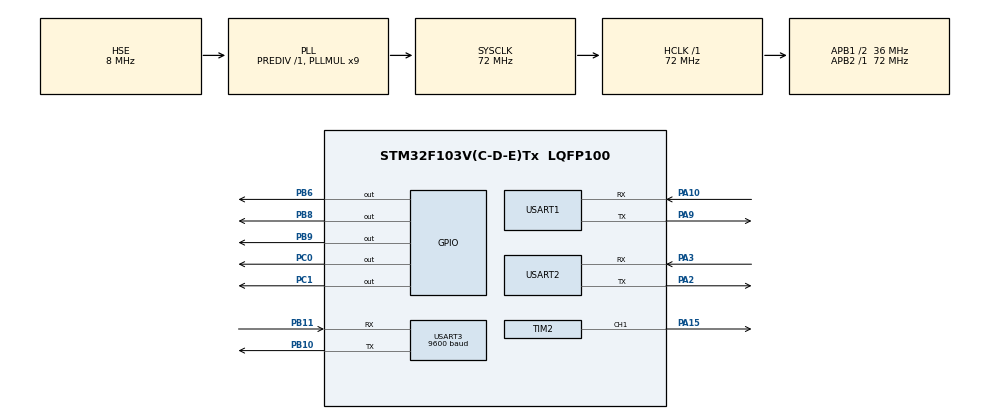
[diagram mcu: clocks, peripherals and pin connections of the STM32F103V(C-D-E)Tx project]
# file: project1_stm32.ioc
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IWDG.Prescaler=IWDG_PRESCALER_64
Mcu.Family=STM32F1
Mcu.Name=STM32F103V(C-D-E)Tx
Mcu.Package=LQFP100
NVIC.PriorityGroup=NVIC_PRIORITYGROUP_4
NVIC.TIM7_IRQn=true\:15\:0\:false\:false\:true\:false\:true\:true
NVIC.TimeBase=TIM7_IRQn
NVIC.TimeBaseIP=TIM7
NVIC.USART2_IRQn=true\:7\:0\:true\:false\:true\:true\:true\:true
NVIC.USART3_IRQn=true\:6\:0\:true\:false\:true\:true\:true\:true
OSC_IN.Mode=HSE-External-Oscillator
OSC_IN.Signal=RCC_OSC_IN
OSC_OUT.Mode=HSE-External-Oscillator
OSC_OUT.Signal=RCC_OSC_OUT
PA10.Mode=Asynchronous
PA10.Signal=USART1_RX
PA13.Mode=Serial_Wire
PA13.Signal=SYS_JTMS-SWDIO
PA14.Mode=Serial_Wire
PA14.Signal=SYS_JTCK-SWCLK
PA15.Signal=S_TIM2_CH1_ETR
PA2.Mode=Asynchronous
PA2.Signal=USART2_TX
PA3.Mode=Asynchronous
PA3.Signal=USART2_RX
PA9.Mode=Asynchronous
PA9.Signal=USART1_TX
PB10.Mode=Asynchronous
PB10.Signal=USART3_TX
PB11.Mode=Asynchronous
PB11.Signal=USART3_RX
PB6.GPIO_ModeDefaultOutputPP=GPIO_MODE_OUTPUT_OD
PB6.GPIO_PuPd=GPIO_PULLUP
PB6.GPIO_Speed=GPIO_SPEED_FREQ_HIGH
PB6.PinState=GPIO_PIN_SET
PB6.Signal=GPIO_Output
PB8.GPIO_ModeDefaultOutputPP=GPIO_MODE_OUTPUT_OD
PB8.GPIO_PuPd=GPIO_PULLUP
PB8.GPIO_Speed=GPIO_SPEED_FREQ_HIGH
PB8.PinState=GPIO_PIN_SET
PB8.Signal=GPIO_Output
PB9.GPIO_ModeDefaultOutputPP=GPIO_MODE_OUTPUT_OD
PB9.GPIO_PuPd=GPIO_PULLUP
PB9.GPIO_Speed=GPIO_SPEED_FREQ_HIGH
PB9.PinState=GPIO_PIN_SET
PB9.Signal=GPIO_Output
PC0.Signal=GPIO_Output
PC1.GPIO_ModeDefaultOutputPP=GPIO_MODE_OUTPUT_OD
PC1.GPIO_PuPd=GPIO_PULLUP
PC1.GPIO_Speed=GPIO_SPEED_FREQ_HIGH
PC1.PinState=GPIO_PIN_SET
PC1.Signal=GPIO_Output
PC14-OSC32_IN.Mode=LSE-External-Oscillator
PC14-OSC32_IN.Signal=RCC_OSC32_IN
PC15-OSC32_OUT.Mode=LSE-External-Oscillator
PC15-OSC32_OUT.Signal=RCC_OSC32_OUT
ProjectManager.HeapSize=0x200
ProjectManager.StackSize=0x400
ProjectManager.TargetToolchain=CMake
RCC.AHBFreq_Value=72000000
RCC.APB1CLKDivider=RCC_HCLK_DIV2
RCC.APB1Freq_Value=36000000
RCC.APB1TimFreq_Value=72000000
RCC.APB2Freq_Value=72000000
RCC.APB2TimFreq_Value=72000000
RCC.HCLKFreq_Value=72000000
RCC.PLLMUL=RCC_PLL_MUL9
RCC.PLLSourceVirtual=RCC_PLLSOURCE_HSE
RCC.SYSCLKFreq_VALUE=72000000
RCC.SYSCLKSource=RCC_SYSCLKSOURCE_PLLCLK
RCC.USBFreq_Value=72000000
SH.S_TIM2_CH1_ETR.0=TIM2_CH1,PWM Generation1 CH1
TIM2.AutoReloadPreload=TIM_AUTORELOAD_PRELOAD_ENABLE
TIM2.Channel-PWM\ Generation1\ CH1=TIM_CHANNEL_1
TIM2.Period=19999
TIM2.Prescaler=71
TIM6.AutoReloadPreload=TIM_AUTORELOAD_PRELOAD_ENABLE
TIM6.Prescaler=71
USART1.VirtualMode=VM_ASYNC
USART2.VirtualMode=VM_ASYNC
USART3.BaudRate=9600
USART3.VirtualMode=VM_ASYNC
VP_IWDG_VS_IWDG.Mode=IWDG_Activate
VP_SYS_VS_tim7.Mode=TIM7
VP_TIM2_VS_ClockSourceINT.Mode=Internal
VP_TIM6_VS_ClockSourceINT.Mode=Enable_Timer
board=custom

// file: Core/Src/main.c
/* USER CODE BEGIN Header */
/**
  ******************************************************************************
  * @file           : main.c
  * @brief          : Main program body
  ******************************************************************************
  * @attention
  *
  * Copyright (c) 2026 STMicroelectronics.
  * All rights reserved.
  *
  * This software is licensed under terms that can be found in the LICENSE file
  * in the root directory of this software component.
  * If no LICENSE file comes with this software, it is provided AS-IS.
  *
  ******************************************************************************
  */
/* USER CODE END Header */
#include "main.h"
#include "iwdg.h"
#include "tim.h"
#include "usart.h"
#include "gpio.h"

/* USER CODE BEGIN Includes */
#include "app.hpp"
#include "FreeRTOS/FreeRTOS.h"
#include "FreeRTOS/semphr.h"
/* USER CODE END Includes */

void SystemClock_Config(void);

/* USER CODE BEGIN 0 */

// printf 重定向 -> USART1 (带互斥锁，FreeRTOS 多任务安全)
extern SemaphoreHandle_t uart_mutex;

int __io_putchar(int ch)
{
    if (uart_mutex != NULL)
        xSemaphoreTake(uart_mutex, portMAX_DELAY);

    HAL_UART_Transmit(&huart1, (uint8_t *)&ch, 1, HAL_MAX_DELAY);

    if (uart_mutex != NULL)
        xSemaphoreGive(uart_mutex);

    return ch;
}

/* USER CODE END 0 */

int main(void)
{

  /* MCU Configuration--------------------------------------------------------*/

  /* Reset of all peripherals, Initializes the Flash interface and the Systick. */
  HAL_Init();

  /* Configure the system clock */
  SystemClock_Config();

  /* Initialize all configured peripherals */
  MX_GPIO_Init();
  MX_TIM2_Init();
  MX_USART1_UART_Init();
  MX_USART2_UART_Init();
  MX_TIM6_Init();
  MX_USART3_UART_Init();
  MX_IWDG_Init();
  /* USER CODE BEGIN 2 */
  HAL_TIM_Base_Start(&htim6);
  start_freertos();
  /* USER CODE END 2 */

  /* Infinite loop */
  while (1)
  {

  }
}

void SystemClock_Config(void)
{
  RCC_OscInitTypeDef RCC_OscInitStruct = {0};
  RCC_ClkInitTypeDef RCC_ClkInitStruct = {0};

  /** Initializes the RCC Oscillators according to the specified parameters
  * in the RCC_OscInitTypeDef structure.
  */
  RCC_OscInitStruct.OscillatorType = RCC_OSCILLATORTYPE_LSI|RCC_OSCILLATORTYPE_HSE;
  RCC_OscInitStruct.HSEState = RCC_HSE_ON;
  RCC_OscInitStruct.HSEPredivValue = RCC_HSE_PREDIV_DIV1;
  RCC_OscInitStruct.HSIState = RCC_HSI_ON;
  RCC_OscInitStruct.LSIState = RCC_LSI_ON;
  RCC_OscInitStruct.PLL.PLLState = RCC_PLL_ON;
  RCC_OscInitStruct.PLL.PLLSource = RCC_PLLSOURCE_HSE;
  RCC_OscInitStruct.PLL.PLLMUL = RCC_PLL_MUL9;
  if (HAL_RCC_OscConfig(&RCC_OscInitStruct) != HAL_OK)
  {
    Error_Handler();
  }

  /** Initializes the CPU, AHB and APB buses clocks
  */
  RCC_ClkInitStruct.ClockType = RCC_CLOCKTYPE_HCLK|RCC_CLOCKTYPE_SYSCLK
                              |RCC_CLOCKTYPE_PCLK1|RCC_CLOCKTYPE_PCLK2;
  RCC_ClkInitStruct.SYSCLKSource = RCC_SYSCLKSOURCE_PLLCLK;
  RCC_ClkInitStruct.AHBCLKDivider = RCC_SYSCLK_DIV1;
  RCC_ClkInitStruct.APB1CLKDivider = RCC_HCLK_DIV2;
  RCC_ClkInitStruct.APB2CLKDivider = RCC_HCLK_DIV1;

  if (HAL_RCC_ClockConfig(&RCC_ClkInitStruct, FLASH_LATENCY_2) != HAL_OK)
  {
    Error_Handler();
  }
}

void HAL_TIM_PeriodElapsedCallback(TIM_HandleTypeDef *htim)
{
  if (htim->Instance == TIM7)
  {
    HAL_IncTick();
  }
}

void Error_Handler(void)
{
  __disable_irq();
  while (1)
  {
  }
}
